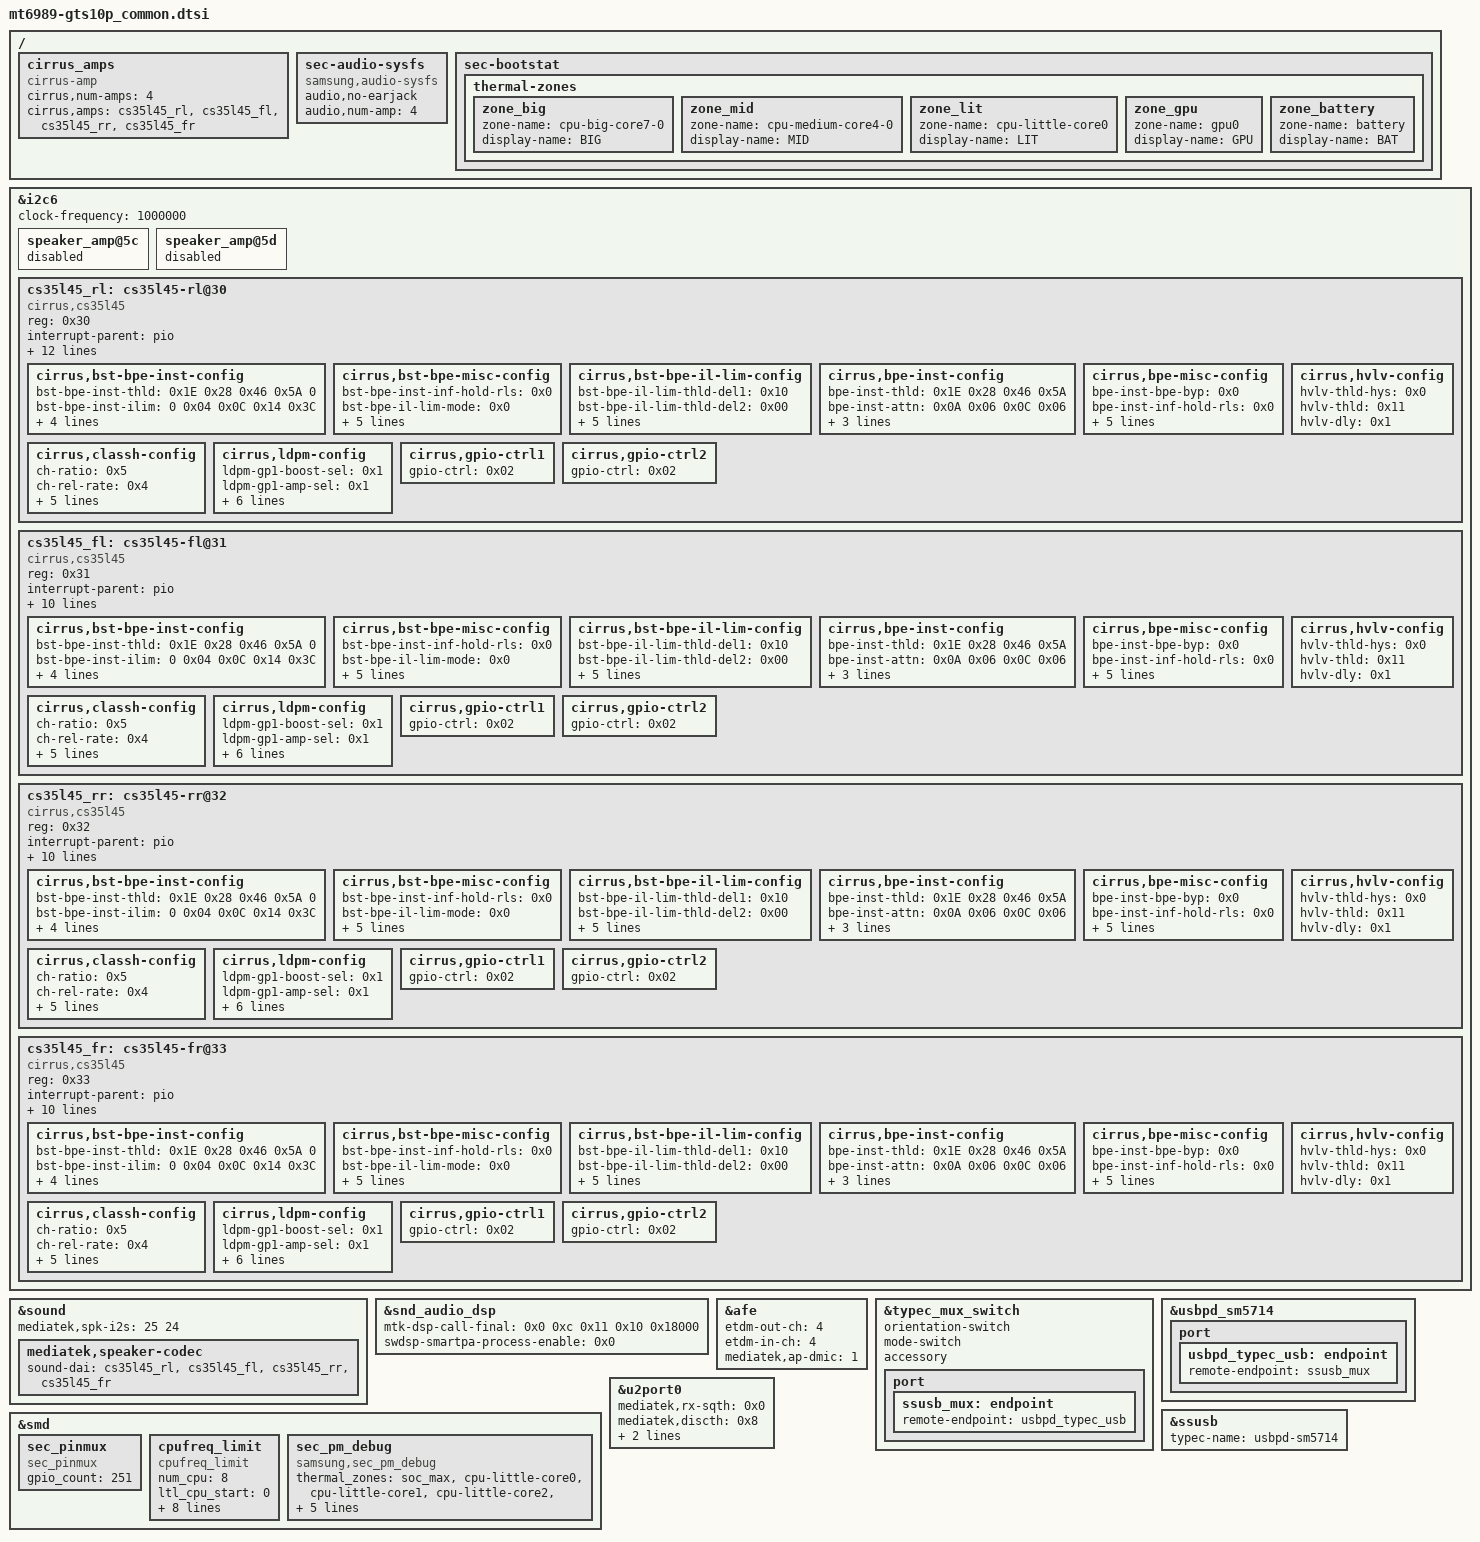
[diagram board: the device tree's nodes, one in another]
/* Generated by Samsung for MTK vendor board
 * If these files should be changed, then please make a sync with MTK
*/

/* Add Samsung configuration over here */

/ {
	fragment@model {
		target-path = "/";
		__overlay__ {
			cirrus_amps {
				compatible = "cirrus-amp";
				cirrus,num-amps = <4>;
				/* i2c addr 0x30, 0x31, 0x32, 0x33 */
				cirrus,amps = <&cs35l45_rl &cs35l45_fl &cs35l45_rr &cs35l45_fr>;
			};

			sec-audio-sysfs {
				compatible = "samsung,audio-sysfs";
				status = "okay";
				audio,no-earjack;
				audio,num-amp = <4>;
			};

			sec-bootstat {
				thermal-zones {
					/* max number of thermal-zones is 10 */
					/* max length of display-name is 4 */
					zone_big {
						zone-name = "cpu-big-core7-0";
						display-name = "BIG";
					};
					zone_mid {
						zone-name = "cpu-medium-core4-0";
						display-name = "MID";
					};
					zone_lit {
						zone-name = "cpu-little-core0";
						display-name = "LIT";
					};
					zone_gpu {
						zone-name = "gpu0";
						display-name = "GPU";
					};
					zone_battery {
						zone-name = "battery";
						display-name = "BAT";
					};
				};
			};

		}; /* end of __overlay__ */
	}; /* end of fragment */
}; /* end of root */

&i2c6 {
	clock-frequency = <1000000>;

	speaker_amp@5c {
		status = "disabled";
	};

	speaker_amp@5d {
		status = "disabled";
	};

	cs35l45_rl: cs35l45-rl@30 {
		compatible = "cirrus,cs35l45";
		#sound-dai-cells = <0>;
		reg = <0x30>;
		status = "okay";
		interrupt-parent = <&pio>;
		interrupts = <7 8>;
		power-gpios = <&pio 111 0>;
		reset-gpios = <&pio 108 0>;
		sound-name-prefix = "RL"; /* RearLeft */
		cirrus,mfd-suffix = "";
		cirrus,bd-suffix = "_2";
		cirrus,use-tdm-slots;
		cirrus,asp-sdout-hiz-ctrl = <0x3>;

		cirrus,ngate-ch1-hold = <0x2>;
		cirrus,ngate-ch1-thr = <0x6>;
		cirrus,ngate-ch2-hold = <0x2>;
		cirrus,ngate-ch2-thr = <0x6>;

		cirrus,bst-bpe-inst-config {
			bst-bpe-inst-thld = <0x1E 0x28 0x46 0x5A 0>;
			bst-bpe-inst-ilim = <0 0x04 0x0C 0x14 0x3C>;
			bst-bpe-inst-ss-ilim = <0 0x00 0x04 0x08 0x1C>;
			bst-bpe-inst-atk-rate = <0 0x3 0x6 0x6 0>;
			bst-bpe-inst-hold-time = <0x2 0x2 0x2 0x2 0>;
			bst-bpe-inst-rls-rate = <0x06 0x06 0x06 0x06 0>;
		};

		cirrus,bst-bpe-misc-config {
			bst-bpe-inst-inf-hold-rls = <0x0>;
			bst-bpe-il-lim-mode = <0x0>;
			bst-bpe-out-opmode-sel = <0x0>;
			bst-bpe-inst-l3-byp = <0x1>;
			bst-bpe-inst-l2-byp = <0x1>;
			bst-bpe-inst-l1-byp = <0x0>;
			bst-bpe-filt-sel = <0x0>;
		};

		cirrus,bst-bpe-il-lim-config {
			bst-bpe-il-lim-thld-del1 = <0x10>;
			bst-bpe-il-lim-thld-del2 = <0x00>;
			bst-bpe-il-lim1-thld = <0x2c>;
			bst-bpe-il-lim-thld-hyst = <0x00>;
			bst-bpe-il-lim-dly-hyst = <0x00>;
			bst-bpe-il-lim2-dly = <0x04>;
			bst-bpe-il-lim1-dly = <0x04>;
		};

		cirrus,bpe-inst-config {
			bpe-inst-thld = <0x1E 0x28 0x46 0x5A>;
			bpe-inst-attn = <0x0A 0x06 0x0C 0x06>;
			bpe-inst-atk-rate = <0x00 0x01 0x06 0x06>;
			bpe-inst-hold-time = <0x02 0x02 0x02 0x02>;
			bpe-inst-rls-rate = <0x0A 0x08 0x05 0x05>;
		};

		cirrus,bpe-misc-config {
			bpe-inst-bpe-byp = <0x0>;
			bpe-inst-inf-hold-rls = <0x0>;
			bpe-inst-l3-byp = <0x1>;
			bpe-inst-l2-byp = <0x1>;
			bpe-inst-l1-byp = <0x0>;
			bpe-mode-sel = <0x0>;
			bpe-filt-sel = <0x0>;
		};

		cirrus,classh-config {
			ch-ratio = <0x5>;
			ch-rel-rate = <0x4>;
			ch-ovb-thld1 = <0x82>;
			ch-ovb-thlddelta = <0x28>;
			ch-vdd-bst-max = <0xFA>;
			ch-ovb-ratio = <0x01>;
			ch-thld1-offset = <0x02d>;
		};

		cirrus,hvlv-config {
			hvlv-thld-hys = <0x0>;
			hvlv-thld = <0x11>;
			hvlv-dly = <0x1>;
		};

		cirrus,ldpm-config {
			ldpm-gp1-boost-sel = <0x1>;
			ldpm-gp1-amp-sel = <0x1>;
			ldpm-gp1-delay = <0x6>;
			ldpm-gp1-pcm-thld = <0x6>;
			ldpm-gp2-imon-sel = <0x1>;
			ldpm-gp2-vmon-sel = <0x1>;
			ldpm-gp2-delay = <0x6>;
			ldpm-gp2-pcm-thld = <0x6>;
		};

		cirrus,gpio-ctrl1 {
			gpio-ctrl = <0x02>;
		};
		cirrus,gpio-ctrl2 {
			gpio-ctrl = <0x02>;
		};
	};

	cs35l45_fl: cs35l45-fl@31 {
		compatible = "cirrus,cs35l45";
		#sound-dai-cells = <0>;
		reg = <0x31>;
		status = "okay";
		interrupt-parent = <&pio>;
		interrupts = <7 8>;
		/* reset-gpios = <&pio 108 0>; */
		sound-name-prefix = "FL"; /* FrontLeft */
		cirrus,mfd-suffix = "_b";
		cirrus,bd-suffix = "_0";
		cirrus,use-tdm-slots;
		cirrus,asp-sdout-hiz-ctrl = <0x3>;

		cirrus,ngate-ch1-hold = <0x2>;
		cirrus,ngate-ch1-thr = <0x6>;
		cirrus,ngate-ch2-hold = <0x2>;
		cirrus,ngate-ch2-thr = <0x6>;

		cirrus,bst-bpe-inst-config {
			bst-bpe-inst-thld = <0x1E 0x28 0x46 0x5A 0>;
			bst-bpe-inst-ilim = <0 0x04 0x0C 0x14 0x3C>;
			bst-bpe-inst-ss-ilim = <0 0x00 0x04 0x08 0x1C>;
			bst-bpe-inst-atk-rate = <0 0x3 0x6 0x6 0>;
			bst-bpe-inst-hold-time = <0x2 0x2 0x2 0x2 0>;
			bst-bpe-inst-rls-rate = <0x06 0x06 0x06 0x06 0>;
		};

		cirrus,bst-bpe-misc-config {
			bst-bpe-inst-inf-hold-rls = <0x0>;
			bst-bpe-il-lim-mode = <0x0>;
			bst-bpe-out-opmode-sel = <0x0>;
			bst-bpe-inst-l3-byp = <0x1>;
			bst-bpe-inst-l2-byp = <0x1>;
			bst-bpe-inst-l1-byp = <0x0>;
			bst-bpe-filt-sel = <0x0>;
		};

		cirrus,bst-bpe-il-lim-config {
			bst-bpe-il-lim-thld-del1 = <0x10>;
			bst-bpe-il-lim-thld-del2 = <0x00>;
			bst-bpe-il-lim1-thld = <0x2c>;
			bst-bpe-il-lim-thld-hyst = <0x00>;
			bst-bpe-il-lim-dly-hyst = <0x00>;
			bst-bpe-il-lim2-dly = <0x04>;
			bst-bpe-il-lim1-dly = <0x04>;
		};

		cirrus,bpe-inst-config {
			bpe-inst-thld = <0x1E 0x28 0x46 0x5A>;
			bpe-inst-attn = <0x0A 0x06 0x0C 0x06>;
			bpe-inst-atk-rate = <0x00 0x01 0x06 0x06>;
			bpe-inst-hold-time = <0x02 0x02 0x02 0x02>;
			bpe-inst-rls-rate = <0x0A 0x08 0x05 0x05>;
		};

		cirrus,bpe-misc-config {
			bpe-inst-bpe-byp = <0x0>;
			bpe-inst-inf-hold-rls = <0x0>;
			bpe-inst-l3-byp = <0x1>;
			bpe-inst-l2-byp = <0x1>;
			bpe-inst-l1-byp = <0x0>;
			bpe-mode-sel = <0x0>;
			bpe-filt-sel = <0x0>;
		};

		cirrus,classh-config {
			ch-ratio = <0x5>;
			ch-rel-rate = <0x4>;
			ch-ovb-thld1 = <0x82>;
			ch-ovb-thlddelta = <0x28>;
			ch-vdd-bst-max = <0xFA>;
			ch-ovb-ratio = <0x01>;
			ch-thld1-offset = <0x02d>;
		};

		cirrus,hvlv-config {
			hvlv-thld-hys = <0x0>;
			hvlv-thld = <0x11>;
			hvlv-dly = <0x1>;
		};

		cirrus,ldpm-config {
			ldpm-gp1-boost-sel = <0x1>;
			ldpm-gp1-amp-sel = <0x1>;
			ldpm-gp1-delay = <0x6>;
			ldpm-gp1-pcm-thld = <0x6>;
			ldpm-gp2-imon-sel = <0x1>;
			ldpm-gp2-vmon-sel = <0x1>;
			ldpm-gp2-delay = <0x6>;
			ldpm-gp2-pcm-thld = <0x6>;
		};

		cirrus,gpio-ctrl1 {
			gpio-ctrl = <0x02>;
		};
		cirrus,gpio-ctrl2 {
			gpio-ctrl = <0x02>;
		};
	};

	cs35l45_rr: cs35l45-rr@32 {
		compatible = "cirrus,cs35l45";
		#sound-dai-cells = <0>;
		reg = <0x32>;
		status = "okay";
		interrupt-parent = <&pio>;
		interrupts = <7 8>;
		/* reset-gpios = <&pio 108 0>; */
		sound-name-prefix = "RR"; /* RearRight */
		cirrus,mfd-suffix = "_r";
		cirrus,bd-suffix = "_3";
		cirrus,use-tdm-slots;
		cirrus,asp-sdout-hiz-ctrl = <0x3>;

		cirrus,ngate-ch1-hold = <0x2>;
		cirrus,ngate-ch1-thr = <0x6>;
		cirrus,ngate-ch2-hold = <0x2>;
		cirrus,ngate-ch2-thr = <0x6>;

		cirrus,bst-bpe-inst-config {
			bst-bpe-inst-thld = <0x1E 0x28 0x46 0x5A 0>;
			bst-bpe-inst-ilim = <0 0x04 0x0C 0x14 0x3C>;
			bst-bpe-inst-ss-ilim = <0 0x00 0x04 0x08 0x1C>;
			bst-bpe-inst-atk-rate = <0 0x3 0x6 0x6 0>;
			bst-bpe-inst-hold-time = <0x2 0x2 0x2 0x2 0>;
			bst-bpe-inst-rls-rate = <0x06 0x06 0x06 0x06 0>;
		};

		cirrus,bst-bpe-misc-config {
			bst-bpe-inst-inf-hold-rls = <0x0>;
			bst-bpe-il-lim-mode = <0x0>;
			bst-bpe-out-opmode-sel = <0x0>;
			bst-bpe-inst-l3-byp = <0x1>;
			bst-bpe-inst-l2-byp = <0x1>;
			bst-bpe-inst-l1-byp = <0x0>;
			bst-bpe-filt-sel = <0x0>;
		};

		cirrus,bst-bpe-il-lim-config {
			bst-bpe-il-lim-thld-del1 = <0x10>;
			bst-bpe-il-lim-thld-del2 = <0x00>;
			bst-bpe-il-lim1-thld = <0x2c>;
			bst-bpe-il-lim-thld-hyst = <0x00>;
			bst-bpe-il-lim-dly-hyst = <0x00>;
			bst-bpe-il-lim2-dly = <0x04>;
			bst-bpe-il-lim1-dly = <0x04>;
		};

		cirrus,bpe-inst-config {
			bpe-inst-thld = <0x1E 0x28 0x46 0x5A>;
			bpe-inst-attn = <0x0A 0x06 0x0C 0x06>;
			bpe-inst-atk-rate = <0x00 0x01 0x06 0x06>;
			bpe-inst-hold-time = <0x02 0x02 0x02 0x02>;
			bpe-inst-rls-rate = <0x0A 0x08 0x05 0x05>;
		};

		cirrus,bpe-misc-config {
			bpe-inst-bpe-byp = <0x0>;
			bpe-inst-inf-hold-rls = <0x0>;
			bpe-inst-l3-byp = <0x1>;
			bpe-inst-l2-byp = <0x1>;
			bpe-inst-l1-byp = <0x0>;
			bpe-mode-sel = <0x0>;
			bpe-filt-sel = <0x0>;
		};

		cirrus,classh-config {
			ch-ratio = <0x5>;
			ch-rel-rate = <0x4>;
			ch-ovb-thld1 = <0x82>;
			ch-ovb-thlddelta = <0x28>;
			ch-vdd-bst-max = <0xFA>;
			ch-ovb-ratio = <0x01>;
			ch-thld1-offset = <0x02d>;
		};

		cirrus,hvlv-config {
			hvlv-thld-hys = <0x0>;
			hvlv-thld = <0x11>;
			hvlv-dly = <0x1>;
		};

		cirrus,ldpm-config {
			ldpm-gp1-boost-sel = <0x1>;
			ldpm-gp1-amp-sel = <0x1>;
			ldpm-gp1-delay = <0x6>;
			ldpm-gp1-pcm-thld = <0x6>;
			ldpm-gp2-imon-sel = <0x1>;
			ldpm-gp2-vmon-sel = <0x1>;
			ldpm-gp2-delay = <0x6>;
			ldpm-gp2-pcm-thld = <0x6>;
		};

		cirrus,gpio-ctrl1 {
			gpio-ctrl = <0x02>;
		};
		cirrus,gpio-ctrl2 {
			gpio-ctrl = <0x02>;
		};
	};

	cs35l45_fr: cs35l45-fr@33 {
		compatible = "cirrus,cs35l45";
		#sound-dai-cells = <0>;
		reg = <0x33>;
		status = "okay";
		interrupt-parent = <&pio>;
		interrupts = <7 8>;
		/* reset-gpios = <&pio 108 0>; */
		sound-name-prefix = "FR"; /* FrontRight */
		cirrus,mfd-suffix = "_br";
		cirrus,bd-suffix = "_1";
		cirrus,use-tdm-slots;
		cirrus,asp-sdout-hiz-ctrl = <0x3>;

		cirrus,ngate-ch1-hold = <0x2>;
		cirrus,ngate-ch1-thr = <0x6>;
		cirrus,ngate-ch2-hold = <0x2>;
		cirrus,ngate-ch2-thr = <0x6>;

		cirrus,bst-bpe-inst-config {
			bst-bpe-inst-thld = <0x1E 0x28 0x46 0x5A 0>;
			bst-bpe-inst-ilim = <0 0x04 0x0C 0x14 0x3C>;
			bst-bpe-inst-ss-ilim = <0 0x00 0x04 0x08 0x1C>;
			bst-bpe-inst-atk-rate = <0 0x3 0x6 0x6 0>;
			bst-bpe-inst-hold-time = <0x2 0x2 0x2 0x2 0>;
			bst-bpe-inst-rls-rate = <0x06 0x06 0x06 0x06 0>;
		};

		cirrus,bst-bpe-misc-config {
			bst-bpe-inst-inf-hold-rls = <0x0>;
			bst-bpe-il-lim-mode = <0x0>;
			bst-bpe-out-opmode-sel = <0x0>;
			bst-bpe-inst-l3-byp = <0x1>;
			bst-bpe-inst-l2-byp = <0x1>;
			bst-bpe-inst-l1-byp = <0x0>;
			bst-bpe-filt-sel = <0x0>;
		};

		cirrus,bst-bpe-il-lim-config {
			bst-bpe-il-lim-thld-del1 = <0x10>;
			bst-bpe-il-lim-thld-del2 = <0x00>;
			bst-bpe-il-lim1-thld = <0x2c>;
			bst-bpe-il-lim-thld-hyst = <0x00>;
			bst-bpe-il-lim-dly-hyst = <0x00>;
			bst-bpe-il-lim2-dly = <0x04>;
			bst-bpe-il-lim1-dly = <0x04>;
		};

		cirrus,bpe-inst-config {
			bpe-inst-thld = <0x1E 0x28 0x46 0x5A>;
			bpe-inst-attn = <0x0A 0x06 0x0C 0x06>;
			bpe-inst-atk-rate = <0x00 0x01 0x06 0x06>;
			bpe-inst-hold-time = <0x02 0x02 0x02 0x02>;
			bpe-inst-rls-rate = <0x0A 0x08 0x05 0x05>;
		};

		cirrus,bpe-misc-config {
			bpe-inst-bpe-byp = <0x0>;
			bpe-inst-inf-hold-rls = <0x0>;
			bpe-inst-l3-byp = <0x1>;
			bpe-inst-l2-byp = <0x1>;
			bpe-inst-l1-byp = <0x0>;
			bpe-mode-sel = <0x0>;
			bpe-filt-sel = <0x0>;
		};

		cirrus,classh-config {
			ch-ratio = <0x5>;
			ch-rel-rate = <0x4>;
			ch-ovb-thld1 = <0x82>;
			ch-ovb-thlddelta = <0x28>;
			ch-vdd-bst-max = <0xFA>;
			ch-ovb-ratio = <0x01>;
			ch-thld1-offset = <0x02d>;
		};

		cirrus,hvlv-config {
			hvlv-thld-hys = <0x0>;
			hvlv-thld = <0x11>;
			hvlv-dly = <0x1>;
		};

		cirrus,ldpm-config {
			ldpm-gp1-boost-sel = <0x1>;
			ldpm-gp1-amp-sel = <0x1>;
			ldpm-gp1-delay = <0x6>;
			ldpm-gp1-pcm-thld = <0x6>;
			ldpm-gp2-imon-sel = <0x1>;
			ldpm-gp2-vmon-sel = <0x1>;
			ldpm-gp2-delay = <0x6>;
			ldpm-gp2-pcm-thld = <0x6>;
		};

		cirrus,gpio-ctrl1 {
			gpio-ctrl = <0x02>;
		};
		cirrus,gpio-ctrl2 {
			gpio-ctrl = <0x02>;
		};
	};
};

&sound {
	mediatek,spk-i2s = <25 24>;
	mediatek,speaker-codec {
		/* i2c addr 0x30, 0x31, 0x32, 0x33 */
		sound-dai = <&cs35l45_rl>, <&cs35l45_fl>, <&cs35l45_rr>, <&cs35l45_fr>;
	};
};

/* feature : $enable $dl_mem $ul_mem $ref_mem $size */
&snd_audio_dsp {
	mtk-dsp-call-final = <0x0 0xc 0x11 0x10 0x18000>;
	swdsp-smartpa-process-enable = <0x0>;
};

&afe {
	etdm-out-ch = <4>;
	etdm-in-ch = <4>;
	mediatek,ap-dmic = <1>;
};

&typec_mux_switch {
	orientation-switch;
	mode-switch;
	accessory;
	port {
		ssusb_mux: endpoint {
			remote-endpoint = <&usbpd_typec_usb>;
		};
	};
};

&usbpd_sm5714 {
	port {
		usbpd_typec_usb: endpoint {
			remote-endpoint = <&ssusb_mux>;
		};
	};
};

&smd {
	
	sec_pinmux {
		status = "okay";
		compatible = "sec_pinmux";

		gpio_count = <251>;
	};
	
	cpufreq_limit {
		status = "okay";
		compatible = "cpufreq_limit";

		num_cpu = <8>;
		ltl_cpu_start = <0>;
		mid_cpu_start = <4>;
		big_cpu_start = <7>;
		ltl_min_lock_freq = <1200000>;
		big_max_lock_freq = <800000>;
		ltl_divider = <4>;

		ltl_boost_table = <
			/*900000 1100000*/
			600000 1100000
		>;

		ltl_limit_table = <
			2900000	4294967295	/* 2900000 ~ : max freq */
			2600000	1900000
			1000000	1600000		/* 1000000 ~ under 2600000: 1600000 */
		>;
	};

	sec_pm_debug {
	status = "okay";
	compatible = "samsung,sec_pm_debug";

	thermal_zones = "soc_max",
					"cpu-little-core0", "cpu-little-core1", "cpu-little-core2", "cpu-little-core3",
					"cpu-medium-core4-0", "cpu-medium-core4-1", "cpu-medium-core5-0", "cpu-medium-core5-1",
					"cpu-medium-core6-0", "cpu-medium-core6-1", "cpu-big-core7-0", "cpu-big-core7-1",
					/*"cpu-dsu0", "cpu-dsu1", "cpu-dsu2", "cpu-dsu3", 
					"soc-top0", "soc-top1", "soc-top2", "soc-top3",
					"soc-bot0", "soc-bot1", "soc-bot2", "soc-bot3",
					"apu-a0", "apu-a1", "apu-a2", "apu-a3", "apu-b0",*/
					"gpu0", "gpu1", "gpu2";
	};
};

&u2port0 {
	mediatek,rx-sqth = <0x0>;
	mediatek,discth = <0x8>;
	mediatek,rev6 = <0x3>;
	mediatek,eye-vrt = <0x7>;
};

&ssusb {
	typec-name = "usbpd-sm5714";
};
